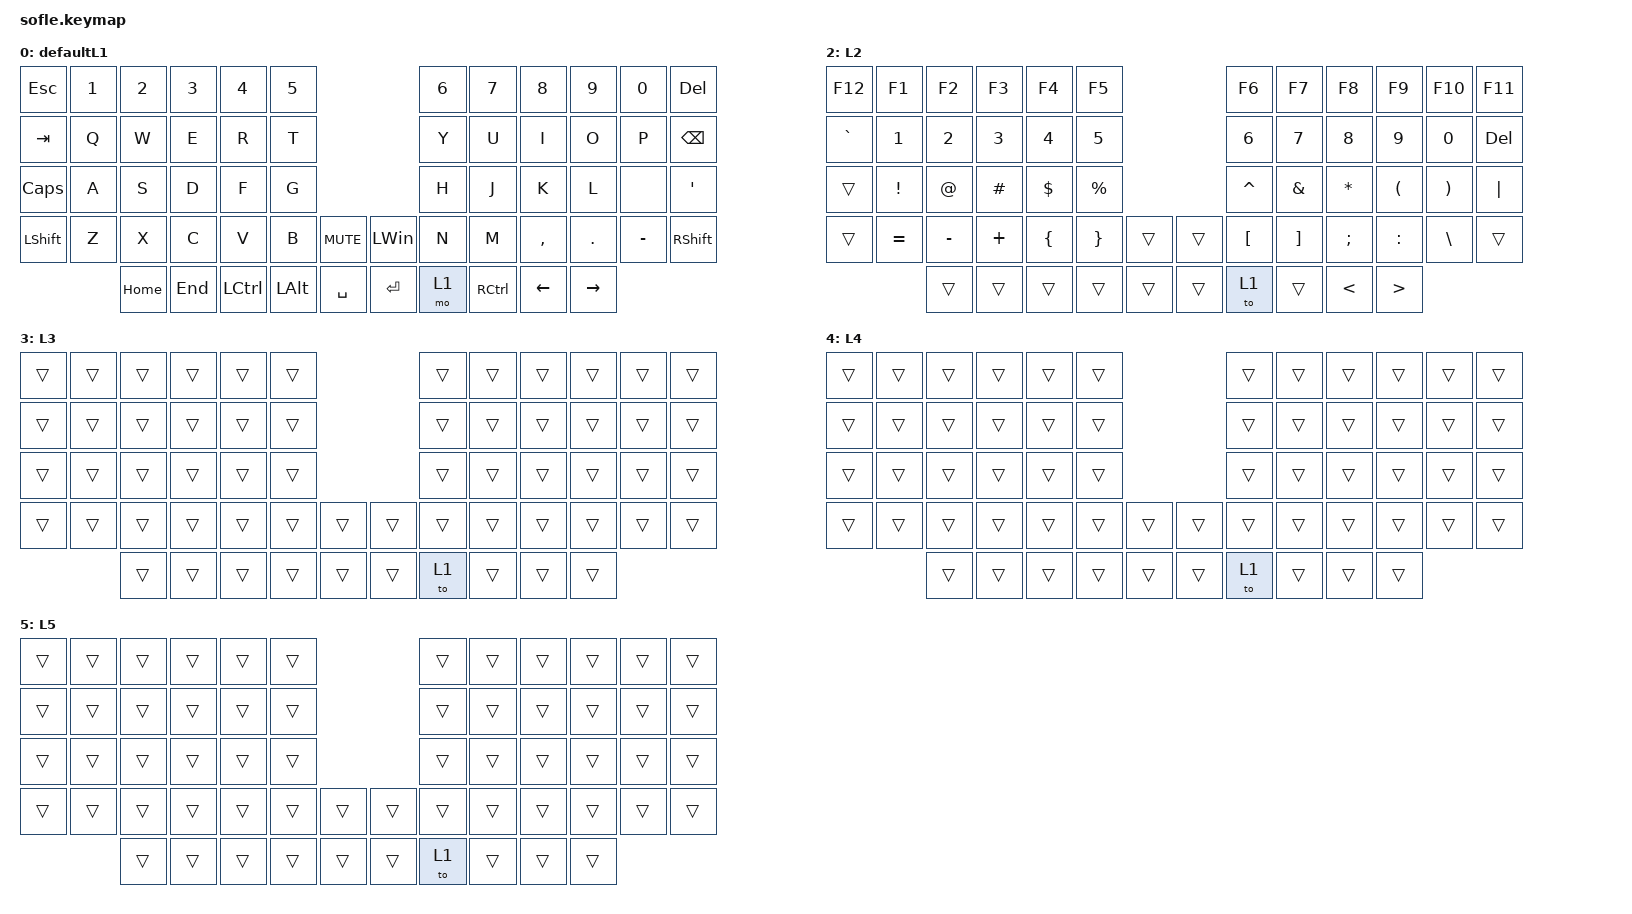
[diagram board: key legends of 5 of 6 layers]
/*
 * Copyright (c) 2020 The ZMK Contributors
 *
 * SPDX-License-Identifier: MIT
 */

#include <behaviors.dtsi>
#include <dt-bindings/zmk/bt.h>
#include <dt-bindings/zmk/ext_power.h>
#include <dt-bindings/zmk/keys.h>
#include <dt-bindings/zmk/rgb.h>

#define BASE 0
#define LOWER 1
#define RAISE 2
#define ADJUST 3

/ {
    // Activate ADJUST layer by pressing raise and lower

    conditional_layers {
        compatible = "zmk,conditional-layers";

        changeL1 {
            if-layers = <1>;
            then-layer = <0>;
        };
    };

    keymap {
        compatible = "zmk,keymap";

        L1 {
            display-name = "defaultL1";

            // ------------------------------------------------------------------------------------------------------------
            // |   `   |  1  |  2  |  3   |  4   |  5   |                   |  6   |  7    |  8    |  9   |   0   |   -   |
            // |  ESC  |  Q  |  W  |  E   |  R   |  T   |                   |  Y   |  U    |  I    |  O   |   P   | BKSPC |
            // |  TAB  |  A  |  S  |  D   |  F   |  G   |                   |  H   |  J    |  K    |  L   |   ;   |   '   |
            // | SHIFT |  Z  |  X  |  C   |  V   |  B   |  MUTE  |  |       |  N   |  M    |  ,    |  .   |   /   |  DEL  |
            //               | GUI | ALT  | CTRL | LOWER|  ENTER |  | SPACE | RAISE|   [   |   ]   |  =   |

            bindings = <
&kp ESCAPE    &kp NUMBER_1  &kp NUMBER_2  &kp NUMBER_3  &kp N4            &kp N5                                    &kp N6  &kp N7             &kp N8     &kp N9     &kp N0     &kp DEL
&kp TAB       &kp Q         &kp W         &kp E         &kp R             &kp T                                     &kp Y   &kp U              &kp I      &kp O      &kp P      &kp BSPC
&kp CAPSLOCK  &kp A         &kp S         &kp D         &kp F             &kp G                                     &kp H   &kp J              &kp K      &kp L      &none      &kp SQT
&kp LSHFT     &kp Z         &kp X         &kp C         &kp V             &kp B         &kp C_MUTE    &kp LEFT_WIN  &kp N   &kp M              &kp COMMA  &kp DOT    &kp MINUS  &kp RIGHT_SHIFT
                            &kp HOME      &kp END       &kp LEFT_CONTROL  &kp LEFT_ALT  &kp SPACE     &kp ENTER     &mo 1   &kp RIGHT_CONTROL  &kp LEFT   &kp RIGHT
            >;

            sensor-bindings =
                <&inc_dec_kp C_VOL_UP C_VOLUME_DOWN>,
                <&inc_dec_kp PG_DN PG_UP>;
        };

        ajustes {
            // ----------------------------------------------------------------------------------------------------------------------------
            // | BTCLR  |  BT1    |  BT2    |   BT3   |   BT4   |   BT5   |                  |      |      |       |      |       |       |
            // | EXTPWR | RGB_HUD | RGB_HUI | RGB_SAD | RGB_SAI | RGB_EFF |                  |      |      |       |      |       |       |
            // |        | RGB_BRD | RGB_BRI |         |         |         |                  |      |      |       |      |       |       |
            // |        |         |         |         |         |         | RGB_TOG | |      |      |      |       |      |       |       |
            //                    |         |         |         |         |         | |      |      |      |       |      |

            display-name = "adjust";
            bindings = <
&bt BT_CLR         &bt BT_SEL 0     &bt BT_SEL 1     &bt BT_SEL 2     &bt BT_SEL 3     &bt BT_SEL 4                               &to 0  &to 2  &to 3  &to 4  &to 5  &none
&ext_power EP_TOG  &rgb_ug RGB_HUD  &rgb_ug RGB_HUI  &rgb_ug RGB_SAD  &rgb_ug RGB_SAI  &rgb_ug RGB_EFF                            &none  &none  &none  &none  &none  &none
&none              &rgb_ug RGB_BRD  &rgb_ug RGB_BRI  &none            &none            &none                                      &none  &none  &none  &none  &none  &none
&none              &none            &none            &none            &none            &none            &rgb_ug RGB_TOG    &none  &none  &none  &none  &none  &none  &none
                                    &none            &none            &none            &none            &studio_unlock     &none  &none  &none  &none
            >;

            sensor-bindings =
                <&inc_dec_kp C_VOLUME_UP C_VOL_DN>,
                <&inc_dec_kp PAGE_DOWN PAGE_UP>;
        };

        L2 {
            display-name = "L2";

            // TODO: Some binds are waiting for shifted keycode support.
            // ------------------------------------------------------------------------------------------------------------
            // |       |  F1 |  F2 |  F3  |  F4  |  F5  |                   |  F6  |  F7   |  F8   |  F9  |  F10  |  F11  |
            // |   `   |  1  |  2  |  3   |  4   |  5   |                   |  6   |  7    |  8    |  9   |   0   |  F12  |
            // |       |  !  |  @  |  #   |  $   |  %   |                   |  ^   |  &    |  *    |  (   |   )   |   |   |
            // |       |  =  |  -  |  +   |  {   |  }   |        |  |       |  [   |  ]    |  ;    |  :   |   \   |       |
            //               |     |      |      |      |        |  |       |      |       |       |      |

            bindings = <
&kp F12    &kp F1     &kp F2     &kp F3    &kp F4    &kp F5                       &kp F6     &kp F7    &kp F8         &kp F9            &kp F10   &kp F11
&kp GRAVE  &kp N1     &kp N2     &kp N3    &kp N4    &kp N5                       &kp N6     &kp N7    &kp N8         &kp N9            &kp N0    &kp DELETE
&trans     &kp EXCL   &kp AT     &kp HASH  &kp DLLR  &kp PRCNT                    &kp CARET  &kp AMPS  &kp ASTRK      &kp LPAR          &kp RPAR  &kp PIPE
&trans     &kp EQUAL  &kp MINUS  &kp PLUS  &kp LBRC  &kp RBRC   &trans    &trans  &kp LBKT   &kp RBKT  &kp SEMI       &kp COLON         &kp BSLH  &trans
                      &trans     &trans    &trans    &trans     &trans    &trans  &to 1      &trans    &kp LESS_THAN  &kp GREATER_THAN
            >;

            sensor-bindings =
                <&inc_dec_kp C_VOL_UP C_VOLUME_DOWN>,
                <&inc_dec_kp PG_DN PG_UP>;
        };

        L3 {
            bindings = <
&trans  &trans  &trans  &trans  &trans  &trans                    &trans  &trans  &trans  &trans  &trans  &trans
&trans  &trans  &trans  &trans  &trans  &trans                    &trans  &trans  &trans  &trans  &trans  &trans
&trans  &trans  &trans  &trans  &trans  &trans                    &trans  &trans  &trans  &trans  &trans  &trans
&trans  &trans  &trans  &trans  &trans  &trans  &trans    &trans  &trans  &trans  &trans  &trans  &trans  &trans
                &trans  &trans  &trans  &trans  &trans    &trans  &to 1   &trans  &trans  &trans
            >;

            sensor-bindings =
                <&inc_dec_kp C_VOL_UP C_VOLUME_DOWN>,
                <&inc_dec_kp PAGE_DOWN PAGE_UP>;
        };

        L4 {
            bindings = <
&trans  &trans  &trans  &trans  &trans  &trans                    &trans  &trans  &trans  &trans  &trans  &trans
&trans  &trans  &trans  &trans  &trans  &trans                    &trans  &trans  &trans  &trans  &trans  &trans
&trans  &trans  &trans  &trans  &trans  &trans                    &trans  &trans  &trans  &trans  &trans  &trans
&trans  &trans  &trans  &trans  &trans  &trans  &trans    &trans  &trans  &trans  &trans  &trans  &trans  &trans
                &trans  &trans  &trans  &trans  &trans    &trans  &to 1   &trans  &trans  &trans
            >;

            sensor-bindings =
                <&inc_dec_kp C_VOL_UP C_VOLUME_DOWN>,
                <&inc_dec_kp PAGE_DOWN PAGE_UP>;
        };

        L5 {
            bindings = <
&trans  &trans  &trans  &trans  &trans  &trans                    &trans  &trans  &trans  &trans  &trans  &trans
&trans  &trans  &trans  &trans  &trans  &trans                    &trans  &trans  &trans  &trans  &trans  &trans
&trans  &trans  &trans  &trans  &trans  &trans                    &trans  &trans  &trans  &trans  &trans  &trans
&trans  &trans  &trans  &trans  &trans  &trans  &trans    &trans  &trans  &trans  &trans  &trans  &trans  &trans
                &trans  &trans  &trans  &trans  &trans    &trans  &to 1   &trans  &trans  &trans
            >;

            sensor-bindings =
                <&inc_dec_kp C_VOLUME_UP C_VOL_DN>,
                <&inc_dec_kp PAGE_DOWN PAGE_UP>;
        };
    };
};
